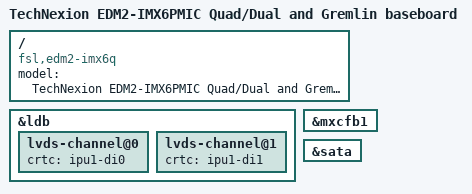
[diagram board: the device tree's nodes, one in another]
/*
 * Copyright 2018 Technexion Ltd.
 *
 * Author: Tapani Utriainen <tapani@technexion.com>
 *
 * The code contained herein is licensed under the GNU General Public
 * License. You may obtain a copy of the GNU General Public License
 * Version 2 or later at the following locations:
 *
 * http://www.opensource.org/licenses/gpl-license.html
 * http://www.gnu.org/copyleft/gpl.html
 */

/dts-v1/;
#include <dt-bindings/interrupt-controller/irq.h>
#include "imx6q.dtsi"
#include "imx6qdl-edm.dtsi"
#include "baseboard_edm2_gremlin.dtsi"

/ {
	model = "TechNexion EDM2-IMX6PMIC Quad/Dual and Gremlin baseboard";
	compatible = "fsl,edm2-imx6q", "fsl,imx6q";
};

&ldb {
	lvds-channel@0 {
		crtc = "ipu1-di0";
	};
	lvds-channel@1 {
		crtc = "ipu1-di1";
	};
};

&mxcfb1 {
	status = "okay";
};

&sata {
	status = "okay";
};
